# MKW30Z4 register map
Vendor: Freescale Semiconductor, Inc.; Series: Kinetis_W; File version: 1.6
CPU: CM0PLUS r0p0, little endian, no MPU, no FPU, VTOR, 2 interrupt priority bits
Registers are 32-bit, read-write, reset 0x0 unless marked. A register's access mark holds for its fields unless they carry their own. Offsets are from the block's base; [hi:lo] are bit positions; {n}, {i} and the like mark numbered series; 'fields as' and 'values as' point back to an identical list.

## BLE_RF_REGS — Bluetooth Low Energy RF Registers
Base 0x4005B000; register names take the prefix BLE_RF_REGS_
0xD00 BLE_PART_ID 16-bit ro reset 0x1 — Bluetooth Low Energy Part ID
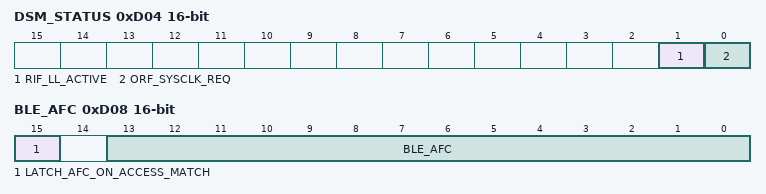
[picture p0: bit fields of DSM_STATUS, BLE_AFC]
0xD04 DSM_STATUS 16-bit ro (reset mask 0xFFFC)
  [1] RIF_LL_ACTIVE — Link Layer Active
  [0] ORF_SYSCLK_REQ — RF Oscillator Requested
0xD08 BLE_AFC 16-bit — Bluetooth Low Energy AFC
  [15] LATCH_AFC_ON_ACCESS_MATCH — Latch AFC Estimation on Access Address Match
    0=BLE_AFC[13:0] is updated whenever preamble is detected; 1=BLE_AFC[13:0] is latched at access address match, and will not be updated until the next access address match
  [13:0] BLE_AFC ro — BLE AFC Result
0xD0C BLE_BSM 16-bit — Bluetooth Low Energy BSM
  [0] BSM_EN_BLE — BLE Bit Streaming Mode Enable
    0=BLE Bit Streaming Mode disabled; 1=BLE Bit Streaming Mode enabled

## CMT — Carrier Modulator Transmitter
Base 0x40062000; register names take the prefix CMT_
0x00 CGH1 8-bit reset not defined — CMT Carrier Generator High Data Register 1
  [7:0] PH — Primary Carrier High Time Data Value
0x01 CGL1 8-bit reset not defined — CMT Carrier Generator Low Data Register 1
  [7:0] PL — Primary Carrier Low Time Data Value
0x02 CGH2 8-bit reset not defined — CMT Carrier Generator High Data Register 2
  [7:0] SH — Secondary Carrier High Time Data Value
0x03 CGL2 8-bit reset not defined — CMT Carrier Generator Low Data Register 2
  [7:0] SL — Secondary Carrier Low Time Data Value
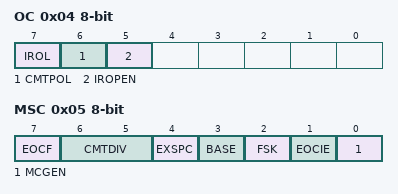
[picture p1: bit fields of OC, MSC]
0x04 OC 8-bit — CMT Output Control Register
  [7] IROL — IRO Latch Control
  [6] CMTPOL — CMT Output Polarity
    0=The IRO signal is active-low; 1=The IRO signal is active-high
  [5] IROPEN — IRO Pin Enable
    0=The IRO signal is disabled; 1=The IRO signal is enabled as output
0x05 MSC 8-bit — CMT Modulator Status and Control Register
  [7] EOCF ro — End Of Cycle Status Flag
    0=End of modulation cycle has not occured since the flag last cleared; 1=End of modulator cycle has occurred
  [6:5] CMTDIV — CMT Clock Divide Prescaler
    0=IF * 1; 1=IF * 2; 2=IF * 4; 3=IF * 8
  [4] EXSPC — Extended Space Enable
    0=Extended space is disabled; 1=Extended space is enabled
  [3] BASE — Baseband Enable
    0=Baseband mode is disabled; 1=Baseband mode is enabled
  [2] FSK — FSK Mode Select
    0=The CMT operates in Time or Baseband mode; 1=The CMT operates in FSK mode
  [1] EOCIE — End of Cycle Interrupt Enable
    0=CPU interrupt is disabled; 1=CPU interrupt is enabled
  [0] MCGEN — Modulator and Carrier Generator Enable
    0=Modulator and carrier generator disabled; 1=Modulator and carrier generator enabled
0x06 CMD1 8-bit reset not defined — CMT Modulator Data Register Mark High
  [7:0] MB — MB[15:8]
0x07 CMD2 8-bit reset not defined — CMT Modulator Data Register Mark Low
  [7:0] MB — MB[7:0]
0x08 CMD3 8-bit reset not defined — CMT Modulator Data Register Space High
  [7:0] SB — SB[15:8]
0x09 CMD4 8-bit reset not defined — CMT Modulator Data Register Space Low
  [7:0] SB — SB[7:0]
0x0A PPS 8-bit — CMT Primary Prescaler Register
  [3:0] PPSDIV — Primary Prescaler Divider
    {v}=Bus clock * {v+1} (v=0..15)
0x0B DMA 8-bit — CMT Direct Memory Access Register
  [0] DMA — DMA Enable
    0=DMA transfer request and done are disabled; 1=DMA transfer request and done are enabled

## LLWU — Low leakage wakeup unit
Base 0x4007C000; register names take the prefix LLWU_
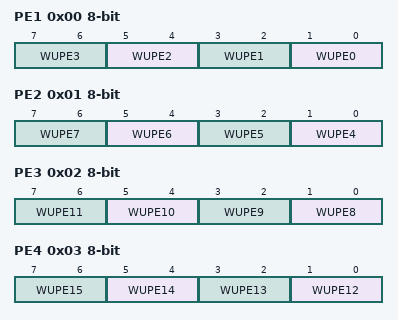
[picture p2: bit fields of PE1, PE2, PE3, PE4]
0x00 PE1 8-bit — LLWU Pin Enable 1 register
  [all] fields
    0=External input pin disabled as wakeup input; 1=External input pin enabled with rising edge detection; 2=External input pin enabled with falling edge detection; 3=External input pin enabled with any change detection
  [2n+1:2n] WUPE{n} (n=0..3) — Wakeup Pin Enable For LLWU_P{n}
0x01 PE2 8-bit — LLWU Pin Enable 2 register
  [all] fields
    values as the fields of PE1
  [2n-7:2n-8] WUPE{n} (n=4..7) — Wakeup Pin Enable For LLWU_P{n}
0x02 PE3 8-bit — LLWU Pin Enable 3 register
  [all] fields
    values as the fields of PE1
  [2n-15:2n-16] WUPE{n} (n=8..11) — Wakeup Pin Enable For LLWU_P{n}
0x03 PE4 8-bit — LLWU Pin Enable 4 register
  [all] fields
    values as the fields of PE1
  [2n-23:2n-24] WUPE{n} (n=12..15) — Wakeup Pin Enable For LLWU_P{n}
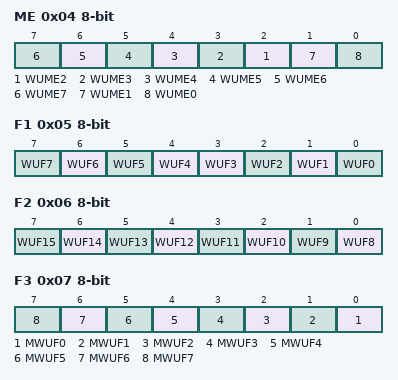
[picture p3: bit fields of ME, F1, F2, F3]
0x04 ME 8-bit — LLWU Module Enable register
  [all] fields
    0=Internal module flag not used as wakeup source; 1=Internal module flag used as wakeup source
  [n] WUME{n} (n=2..7) — Wakeup Module Enable For Module {n}
  [1] WUME1 — Wakeup Module Enable for Module 1
  [0] WUME0 — Wakeup Module Enable For Module 0
0x05 F1 8-bit — LLWU Flag 1 register
  [n] WUF{n} (n=4..7) — Wakeup Flag For LLWU_P{n}
    0=LLWU_P{n} input was not a wakeup source; 1=LLWU_P{n} input was a wakeup source
  [3] WUF3 — Wakeup Flag For LLWU_P3
    0=LLWU_P3 input was not a wake-up source; 1=LLWU_P3 input was a wake-up source
  [2] WUF2 — Wakeup Flag For LLWU_P2
    0=LLWU_P2 input was not a wakeup source; 1=LLWU_P2 input was a wakeup source
  [1] WUF1 — Wakeup Flag For LLWU_P1
    0=LLWU_P1 input was not a wakeup source; 1=LLWU_P1 input was a wakeup source
  [0] WUF0 — Wakeup Flag For LLWU_P0
    0=LLWU_P0 input was not a wakeup source; 1=LLWU_P0 input was a wakeup source
0x06 F2 8-bit — LLWU Flag 2 register
  [n-8] WUF{n} (n=8..15) — Wakeup Flag For LLWU_P{n}
    values as F1.WUF4
0x07 F3 8-bit ro — LLWU Flag 3 register
  [n] MWUF{n} (n=0..7) — Wakeup flag For module {n}
    0=Module {n} input was not a wakeup source; 1=Module {n} input was a wakeup source
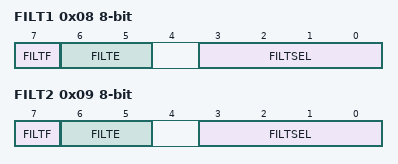
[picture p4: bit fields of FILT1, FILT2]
0x08 FILT1 8-bit — LLWU Pin Filter 1 register
  [7] FILTF — Filter Detect Flag
    0=Pin Filter 1 was not a wakeup source; 1=Pin Filter 1 was a wakeup source
  [6:5] FILTE — Digital Filter On External Pin
    0=Filter disabled; 1=Filter posedge detect enabled; 2=Filter negedge detect enabled; 3=Filter any edge detect enabled
  [3:0] FILTSEL — Filter Pin Select
    0=Select LLWU_P0 for filter; 15=Select LLWU_P15 for filter
0x09 FILT2 8-bit — LLWU Pin Filter 2 register
  [7] FILTF — Filter Detect Flag
    0=Pin Filter 2 was not a wakeup source; 1=Pin Filter 2 was a wakeup source
  [6:5] FILTE — Digital Filter On External Pin
    values as FILT1.FILTE
  [3:0] FILTSEL — Filter Pin Select
    0=Select LLWU_P0 for filter; 15=Select LLWU_P15 for filter
